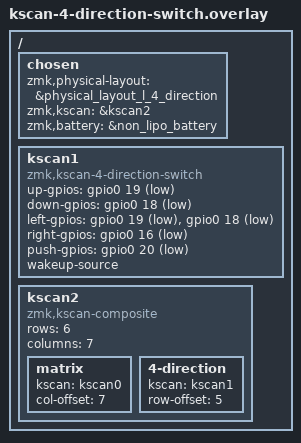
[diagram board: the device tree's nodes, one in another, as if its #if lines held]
#include "kscan-4-direction-switch-layouts.dtsi"

/{
    chosen {
        zmk,physical-layout = &physical_layout_l_4_direction;
        zmk,kscan = &kscan2;
        zmk,battery = &non_lipo_battery;
    };
  
    kscan1: kscan1 {
        compatible = "zmk,kscan-4-direction-switch";

        up-gpios = <&gpio0 19 (GPIO_ACTIVE_LOW | GPIO_PULL_UP)>;
        down-gpios = <&gpio0 18 (GPIO_ACTIVE_LOW | GPIO_PULL_UP)>;
        left-gpios = <&gpio0 19 (GPIO_ACTIVE_LOW | GPIO_PULL_UP)>,
                      <&gpio0 18 (GPIO_ACTIVE_LOW | GPIO_PULL_UP)>;
        right-gpios = <&gpio0 16 (GPIO_ACTIVE_LOW | GPIO_PULL_UP)>;
        push-gpios = <&gpio0 20 (GPIO_ACTIVE_LOW | GPIO_PULL_UP)>;

        wakeup-source;
    };

    kscan2: kscan2 {
        compatible = "zmk,kscan-composite";    
        rows = <6>;
        columns = <7>;

        matrix {
            kscan = <&kscan0>;
#if defined(TORABO_TSUKI_LP_RIGHT)
            col-offset = <7>;
#endif
        };

        4-direction {
            kscan = <&kscan1>;
            row-offset = <5>;
        };
    };
};

